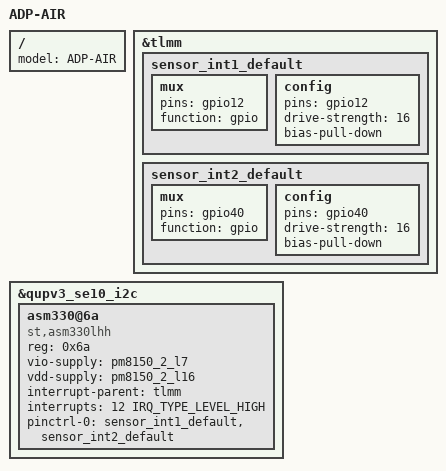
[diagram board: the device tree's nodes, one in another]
// SPDX-License-Identifier: BSD-3-Clause
/*
 * Copyright (c) Qualcomm Technologies, Inc. and/or its subsidiaries.
 */

/* Mimic DT as patched by EDK2 */

#include "sa8155p-v2-adp-air.dts"
#include "sa8155p-adp-air-split-drm.dtsi"

/ {
	/*
	Set 'model' property as given by the overlay (sa8155p-v2-adp-air-overlay.dts).
	It is different from one in sa8155p-v2-adp-air.dts.
	*/
	model = "ADP-AIR";
};
#include "sa8155p-minic-edk2.dtsi"

&tlmm {
	sensor_int1_default: sensor_int1_default {
		mux {
			pins = "gpio12";
			function = "gpio";
		};
		config {
			pins = "gpio12";
			drive-strength = <16>; /* 16 mA */
			bias-pull-down; /* pull down */
		};
	};
	sensor_int2_default: sensor_int2_default {
		mux {
			pins = "gpio40";
			function = "gpio";
		};
		config {
			pins = "gpio40";
			drive-strength = <16>; /* 16 mA */
			bias-pull-down; /* pull down */
		};
	};
};

&qupv3_se10_i2c {
	#address-cells = <1>;
	#size-cells = <0>;
	status = "ok";
	asm330@6a {
		compatible = "st,asm330lhh";
		reg = <0x6a>;
		vio-supply = <&pm8150_2_l7>;
		vdd-supply = <&pm8150_2_l16>;
		interrupt-parent = <&tlmm>;
		interrupts = <12 IRQ_TYPE_LEVEL_HIGH>;
		pinctrl-names = "default";
		pinctrl-0 = <&sensor_int1_default
		&sensor_int2_default>;
	};
};
